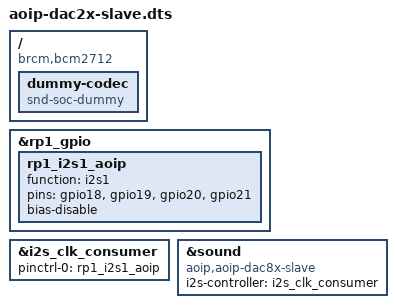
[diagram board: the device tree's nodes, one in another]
/dts-v1/;
/plugin/;

/*
 * AoIP DAC2x + ADC2x Device Tree Overlay — I2S Slave Mode (2채널)
 * compatible: aoip,aoip-dac8x-slave  (기존 커널 모듈 of_match 재사용)
 * RPi(CM5)가 I2S clock consumer(slave) → 외부 컨버터가 BCK/LRCLK 공급
 * i2s_clk_consumer = RP1 i2s@a4000 (I2S1 하드웨어 블록)
 * → GPIO function "i2s1" 이 올바른 핀 먹스 (i2s0 사용 시 DMA 불동작)
 *
 * 8채널(aoip-dac8x-slave) 대비 핀 맵 차이:
 *   - I2S1 로 GPIO18~21 4핀만 먹스 (BCK/LRCLK + 데이터 1쌍)
 *   - GPIO22~27 은 I2S 에서 해제 → 실제 회로의 다른 용도와 핀 충돌 방지
 */

/ {
	compatible = "brcm,bcm2712";

	fragment@0 {
		target = <&rp1_gpio>;
		__overlay__ {
			rp1_i2s1_aoip: rp1_i2s1_aoip {
				function = "i2s1";
				pins = "gpio18", "gpio19", "gpio20", "gpio21";
				bias-disable;
				status = "okay";
			};
		};
	};

	fragment@1 {
		target = <&i2s_clk_consumer>;
		__overlay__ {
			pinctrl-names = "default";
			pinctrl-0 = <&rp1_i2s1_aoip>;
			status = "okay";
		};
	};

	fragment@2 {
		target-path = "/";
		__overlay__ {
			dummy-codec {
				#sound-dai-cells = <0>;
				compatible = "snd-soc-dummy";
				status = "okay";
			};
		};
	};

	fragment@3 {
		target = <&sound>;
		__overlay__ {
			compatible = "aoip,aoip-dac8x-slave";
			i2s-controller = <&i2s_clk_consumer>;
			status = "okay";
		};
	};
};
